# SERDES_16G0 register map
Vendor: Texas Instruments
Registers are 32-bit, read-write, reset 0x0 unless marked. A register's access mark holds for its fields unless they carry their own. Offsets are as the file gives them; [hi:lo] are bit positions; {n}, {i} and the like mark numbered series.

## SERDES_16G0 (part 3 of 5)
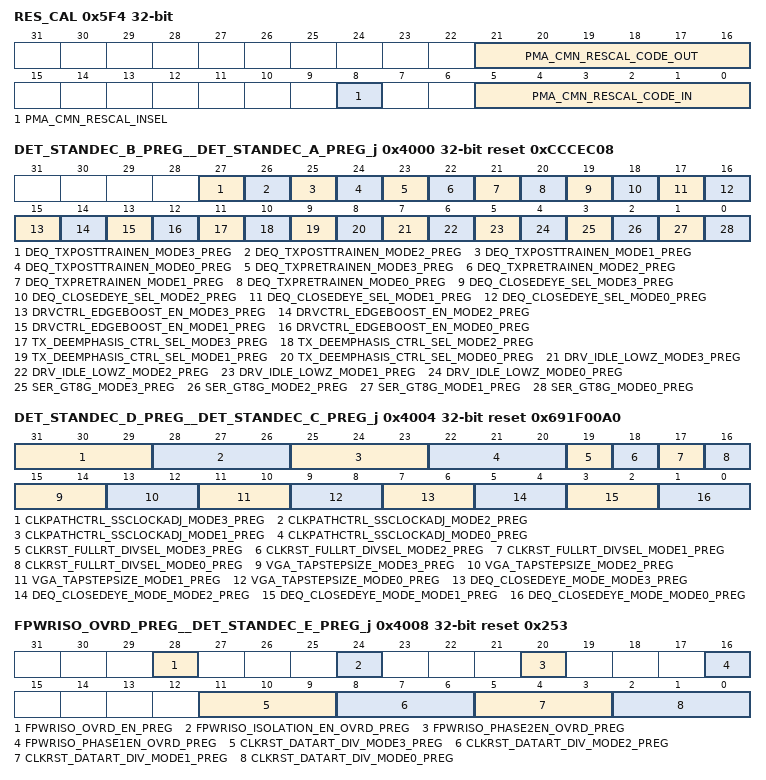
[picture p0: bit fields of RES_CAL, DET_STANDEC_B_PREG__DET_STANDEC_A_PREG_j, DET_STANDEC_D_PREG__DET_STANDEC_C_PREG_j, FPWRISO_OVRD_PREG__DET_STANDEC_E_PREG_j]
0x5F4 RES_CAL access per field — The Resistor Calibration register is used to allow the elimination of the external resistor on multiple macros.
  [21:16] PMA_CMN_RESCAL_CODE_OUT ro — This is the current value of the pma_cmn_rescal_code_out from the SERDES, and can be used to set pma_cmn_rescal_code_in for other macros.
  [8] PMA_CMN_RESCAL_INSEL rw — Common resistor calibration selection -
  [5:0] PMA_CMN_RESCAL_CODE_IN rw — External common resistor calibration result - Resistor calibration result from another Serdes PCIe PHY.
0x5FC DIAG_TEST — The Diagnostic Test Register allows the system to validate the read and write of all data bits.
  [31:0] DIAG_REG — Diagnostic register.
0x4000 DET_STANDEC_B_PREG__DET_STANDEC_A_PREG_j reset 0xCCCEC08 — Standard decoder register A. Offset = 4000h + (j * 400h); where j = 0h to 1h
  [27] DEQ_TXPOSTTRAINEN_MODE3_PREG — This value sets the deq_txposttrainen from the Lane Standards Decoder when xcvr_standard_mode_ln_{15:0}[2:0] is 3'b011.
  [26] DEQ_TXPOSTTRAINEN_MODE2_PREG — This value sets the deq_txposttrainen from the Lane Standards Decoder when xcvr_standard_mode_ln_{15:0}[2:0] is 3'b010.
  [25] DEQ_TXPOSTTRAINEN_MODE1_PREG — This value sets the deq_txposttrainen from the Lane Standards Decoder when xcvr_standard_mode_ln_{15:0}[2:0] is 3'b001.
  [24] DEQ_TXPOSTTRAINEN_MODE0_PREG — This value sets the deq_txposttrainen from the Lane Standards Decoder when xcvr_standard_mode_ln_{15:0}[2:0] is 3'b000.
  [23] DEQ_TXPRETRAINEN_MODE3_PREG — This value sets the deq_txpretrainen from the Lane Standards Decoder when xcvr_standard_mode_ln_{15:0}[2:0] is 3'b011.
  [22] DEQ_TXPRETRAINEN_MODE2_PREG — This value sets the deq_txpretrainen from the Lane Standards Decoder when xcvr_standard_mode_ln_{15:0}[2:0] is 3'b010.
  [21] DEQ_TXPRETRAINEN_MODE1_PREG — This value sets the deq_txpretrainen from the Lane Standards Decoder when xcvr_standard_mode_ln_{15:0}[2:0] is 3'b001.
  [20] DEQ_TXPRETRAINEN_MODE0_PREG — This value sets the deq_txpretrainen from the Lane Standards Decoder when xcvr_standard_mode_ln_{15:0}[2:0] is 3'b000.
  [19] DEQ_CLOSEDEYE_SEL_MODE3_PREG — This value sets the deq_closedeye_sel from the Lane Standards Decoder when xcvr_standard_mode_ln_{15:0}[2:0] is 3'b011.
  [18] DEQ_CLOSEDEYE_SEL_MODE2_PREG — This value sets the deq_closedeye_sel from the Lane Standards Decoder when xcvr_standard_mode_ln_{15:0}[2:0] is 3'b010.
  [17] DEQ_CLOSEDEYE_SEL_MODE1_PREG — This value sets the deq_closedeye_sel from the Lane Standards Decoder when xcvr_standard_mode_ln_{15:0}[2:0] is 3'b001.
  [16] DEQ_CLOSEDEYE_SEL_MODE0_PREG — This value sets the deq_closedeye_sel from the Lane Standards Decoder when xcvr_standard_mode_ln_{15:0}[2:0] is 3'b000.
  [15] DRVCTRL_EDGEBOOST_EN_MODE3_PREG — Active high enable for the transmit driver edgeboost function when xcvr_standard_mode_ln_{15:0}[2:0] is 3'b011.
  [14] DRVCTRL_EDGEBOOST_EN_MODE2_PREG — Active high enable for the transmit driver edgeboost function when xcvr_standard_mode_ln_{15:0}[2:0] is 3'b010.
  [13] DRVCTRL_EDGEBOOST_EN_MODE1_PREG — Active high enable for the transmit driver edgeboost function when xcvr_standard_mode_ln_{15:0}[2:0] is 3'b001.
  [12] DRVCTRL_EDGEBOOST_EN_MODE0_PREG — Active high enable for the transmit driver edgeboost function when xcvr_standard_mode_ln_{15:0}[2:0] is 3'b000.
  [11] TX_DEEMPHASIS_CTRL_SEL_MODE3_PREG — This value sets the tx_deemphasis_ctrl_sel from the Lane Standards Decoder when xcvr_standard_mode_ln_{15:0}[2:0] is 3'b011.
  [10] TX_DEEMPHASIS_CTRL_SEL_MODE2_PREG — This value sets the tx_deemphasis_ctrl_sel from the Lane Standards Decoder when xcvr_standard_mode_ln_{15:0}[2:0] is 3'b010.
  [9] TX_DEEMPHASIS_CTRL_SEL_MODE1_PREG — This value sets the tx_deemphasis_ctrl_sel from the Lane Standards Decoder when xcvr_standard_mode_ln_{15:0}[2:0] is 3'b001.
  [8] TX_DEEMPHASIS_CTRL_SEL_MODE0_PREG — This value sets the tx_deemphasis_ctrl_sel from the Lane Standards Decoder when xcvr_standard_mode_ln_{15:0}[2:0] is 3'b000.
  [7] DRV_IDLE_LOWZ_MODE3_PREG — Asserting this value lowers the impedance of the transmit driver common-mode impedance when xcvr_standard_mode_ln_{15:0}[2:0] is 3'b011.
  [6] DRV_IDLE_LOWZ_MODE2_PREG — Asserting this value lowers the impedance of the transmit driver common-mode impedance when xcvr_standard_mode_ln_{15:0}[2:0] is 3'b010.
  [5] DRV_IDLE_LOWZ_MODE1_PREG — Asserting this value lowers the impedance of the transmit driver common-mode impedance when xcvr_standard_mode_ln_{15:0}[2:0] is 3'b001.
  [4] DRV_IDLE_LOWZ_MODE0_PREG — Asserting this value lowers the impedance of the transmit driver common-mode impedance when xcvr_standard_mode_ln_{15:0}[2:0] is 3'b011.
  [3] SER_GT8G_MODE3_PREG — This value overrides the ser_gt8g from the Lane Standards Decoder when xcvr_standard_mode_ln_{15:0}[2:0] is 3'b011.
  [2] SER_GT8G_MODE2_PREG — This value overrides the ser_gt8g from the Lane Standards Decoder when xcvr_standard_mode_ln_{15:0}[2:0] is 3'b010.
  [1] SER_GT8G_MODE1_PREG — This value overrides the ser_gt8g from the Lane Standards Decoder when xcvr_standard_mode_ln_{15:0}[2:0] is 3'b001.
  [0] SER_GT8G_MODE0_PREG — This value overrides the ser_gt8g from the Lane Standards Decoder when xcvr_standard_mode_ln_{15:0}[2:0] is 3'b000.
0x4004 DET_STANDEC_D_PREG__DET_STANDEC_C_PREG_j reset 0x691F00A0 — Standard decoder register C. Offset = 4004h + (j * 400h); where j = 0h to 1h
  [31:29] CLKPATHCTRL_SSCLOCKADJ_MODE3_PREG — This value sets the clkpathctrl_ssclockadj from the Lane Standards Decoder when xcvr_standard_mode_ln_{15:0}[2:0] is 3'b011.
  [28:26] CLKPATHCTRL_SSCLOCKADJ_MODE2_PREG — This value sets the clkpathctrl_ssclockadj from the Lane Standards Decoder when xcvr_standard_mode_ln_{15:0}[2:0] is 3'b010.
  [25:23] CLKPATHCTRL_SSCLOCKADJ_MODE1_PREG — This value sets the clkpathctrl_ssclockadj from the Lane Standards Decoder when xcvr_standard_mode_ln_{15:0}[2:0] is 3'b001.
  [22:20] CLKPATHCTRL_SSCLOCKADJ_MODE0_PREG — This value sets the clkpathctrl_ssclockadj from the Lane Standards Decoder when xcvr_standard_mode_ln_{15:0}[2:0] is 3'b000.
  [19] CLKRST_FULLRT_DIVSEL_MODE3_PREG — This value sets the clkrst_fullrt_div2sel from the Lane Standards Decoder when xcvr_standard_mode_ln_{15:0}[2:0] is 3'b011.
  [18] CLKRST_FULLRT_DIVSEL_MODE2_PREG — This value sets the clkrst_fullrt_div2sel from the Lane Standards Decoder when xcvr_standard_mode_ln_{15:0}[2:0] is 3'b010.
  [17] CLKRST_FULLRT_DIVSEL_MODE1_PREG — This value sets the clkrst_fullrt_div2sel from the Lane Standards Decoder when xcvr_standard_mode_ln_{15:0}[2:0] is 3'b001.
  [16] CLKRST_FULLRT_DIVSEL_MODE0_PREG — This value sets the clkrst_fullrt_div2sel from the Lane Standards Decoder when xcvr_standard_mode_ln_{15:0}[2:0] is 3'b000.
  [15:14] VGA_TAPSTEPSIZE_MODE3_PREG — Receive data path offset correction current trim when xcvr_standard_mode_ln_{15:0}[2:0] is 3'b011:
  [13:12] VGA_TAPSTEPSIZE_MODE2_PREG — Receive data path offset correction current trim when xcvr_standard_mode_ln_{15:0}[2:0] is 3'b010:
  [11:10] VGA_TAPSTEPSIZE_MODE1_PREG — Receive data path offset correction current trim when xcvr_standard_mode_ln_{15:0}[2:0] is 3'b 001:
  [9:8] VGA_TAPSTEPSIZE_MODE0_PREG — Receive data path offset correction current trim when xcvr_standard_mode_ln_{15:0}[2:0] is 3'b000:
  [7:6] DEQ_CLOSEDEYE_MODE_MODE3_PREG — This value sets the deq_closedeye_mode from the Lane Standards Decoder when xcvr_standard_mode_ln_{15:0}[2:0] is 3'b011.
  [5:4] DEQ_CLOSEDEYE_MODE_MODE2_PREG — This value sets the deq_closedeye_mode from the Lane Standards Decoder when xcvr_standard_mode_ln_{15:0}[2:0] is 3'b010.
  [3:2] DEQ_CLOSEDEYE_MODE_MODE1_PREG — This value sets the deq_closedeye_mode from the Lane Standards Decoder when xcvr_standard_mode_ln_{15:0}[2:0] is 3'b001.
  [1:0] DEQ_CLOSEDEYE_MODE_MODE0_PREG — This value sets the deq_closedeye_mode from the Lane Standards Decoder when xcvr_standard_mode_ln_{15:0}[2:0] is 3'b000.
0x4008 FPWRISO_OVRD_PREG__DET_STANDEC_E_PREG_j reset 0x253 — Standard decoder register E. Offset = 4008h + (j * 400h); where j = 0h to 1h
  [28] FPWRISO_OVRD_EN_PREG — Lane power-gated supply island active high override enable:
  [24] FPWRISO_ISOLATION_EN_OVRD_PREG — Lane power-gated supply island isolation override:
  [20] FPWRISO_PHASE2EN_OVRD_PREG — Lane power-gated supply island phase2en override:
  [16] FPWRISO_PHASE1EN_OVRD_PREG — Lane power-gated supply island phase1en override:
  [11:9] CLKRST_DATART_DIV_MODE3_PREG — This value sets the clkrst_datart_divsel from the Lane Standards Decoder when xcvr_standard_mode_ln_{15:0}[2:0] is 3'b011.
  [8:6] CLKRST_DATART_DIV_MODE2_PREG — This value sets the clkrst_datart_divsel from the Lane Standards Decoder when xcvr_standard_mode_ln_{15:0}[2:0] is 3'b010.
  [5:3] CLKRST_DATART_DIV_MODE1_PREG — This value sets the clkrst_datart_divsel from the Lane Standards Decoder when xcvr_standard_mode_ln_{15:0}[2:0] is 3'b001.
  [2:0] CLKRST_DATART_DIV_MODE0_PREG — This value sets the clkrst_datart_divsel from the Lane Standards Decoder when xcvr_standard_mode_ln_{15:0}[2:0] is 3'b000.
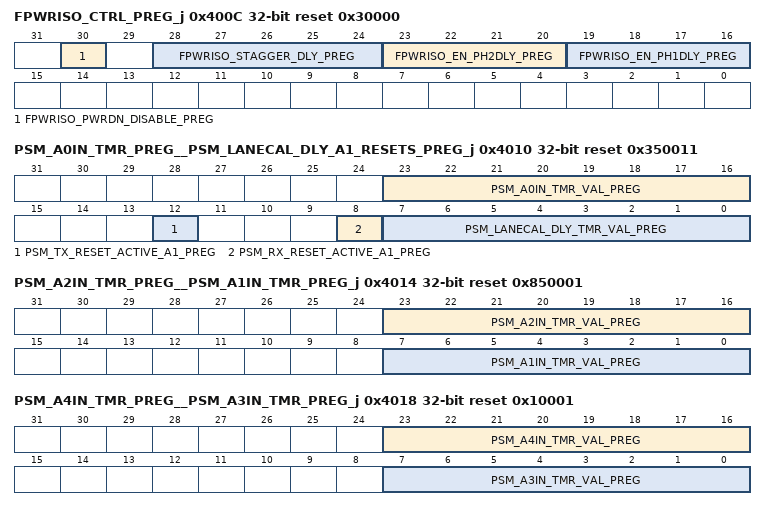
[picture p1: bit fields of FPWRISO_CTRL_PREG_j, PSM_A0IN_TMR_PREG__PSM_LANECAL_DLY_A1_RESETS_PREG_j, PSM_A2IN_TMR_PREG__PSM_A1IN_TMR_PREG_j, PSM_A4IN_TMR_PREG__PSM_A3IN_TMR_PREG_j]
0x400C FPWRISO_CTRL_PREG_j reset 0x30000 — Lane power-gated supply island control register. Offset = 400Ch + (j * 400h); where j = 0h to 1h
  [30] FPWRISO_PWRDN_DISABLE_PREG — Power down disable:
  [28:24] FPWRISO_STAGGER_DLY_PREG — Lane to Lane power island enable/disable stagger time:
  [23:20] FPWRISO_EN_PH2DLY_PREG — Power enable phase 2 timer value:
  [19:16] FPWRISO_EN_PH1DLY_PREG — Power enable phase 1 timer value:
0x4010 PSM_A0IN_TMR_PREG__PSM_LANECAL_DLY_A1_RESETS_PREG_j reset 0x350011 — Power State Machine lane calibration delay timer and A1 resets register. Link control register; only valid in master lane. Offset = 4010h + (j * 400h); where j = 0h to 1h
  [23:16] PSM_A0IN_TMR_VAL_PREG — A0 in delay state timer value :
  [12] PSM_TX_RESET_ACTIVE_A1_PREG — When asserted, the transmit path resets will be asserted in the A1 power state.
  [8] PSM_RX_RESET_ACTIVE_A1_PREG — When asserted, the receive path resets will be asserted in the A1 power state.
  [7:0] PSM_LANECAL_DLY_TMR_VAL_PREG — Lane calibration delay state timer value :
0x4014 PSM_A2IN_TMR_PREG__PSM_A1IN_TMR_PREG_j reset 0x850001 — Power State Machine A1 in delay timer register. Offset = 4014h + (j * 400h); where j = 0h to 1h
  [23:16] PSM_A2IN_TMR_VAL_PREG — A2 in delay state timer value :
  [7:0] PSM_A1IN_TMR_VAL_PREG — A1 in delay state timer value :
0x4018 PSM_A4IN_TMR_PREG__PSM_A3IN_TMR_PREG_j reset 0x10001 — Power State Machine A3 in delay timer register. Link control register; only valid in master lane. Offset = 4018h + (j * 400h); where j = 0h to 1h
  [23:16] PSM_A4IN_TMR_VAL_PREG — A4 in delay state timer value :
  [7:0] PSM_A3IN_TMR_VAL_PREG — A3 in delay state timer value :
0x401C PSM_A0OUT_TMR_PREG_j reset 0x10000 — Power State Machine A0 out delay timer register. Link control register; only valid in master lane. Offset = 401Ch + (j * 400h); where j = 0h to 1h
  [19:16] PSM_A0OUT_TMR_VAL_PREG — A0 out delay state timer value :
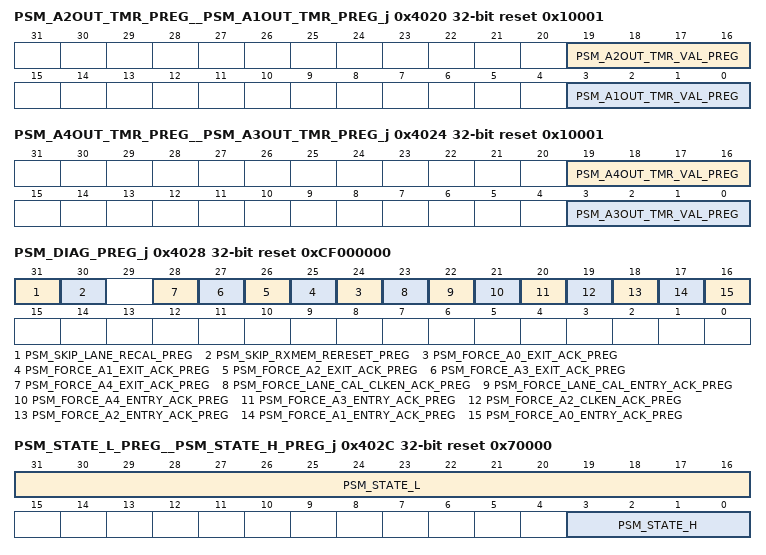
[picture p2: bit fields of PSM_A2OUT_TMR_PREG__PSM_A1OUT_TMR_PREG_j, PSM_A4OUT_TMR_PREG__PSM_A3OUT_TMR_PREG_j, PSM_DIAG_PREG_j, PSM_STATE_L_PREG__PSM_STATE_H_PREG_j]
0x4020 PSM_A2OUT_TMR_PREG__PSM_A1OUT_TMR_PREG_j reset 0x10001 — Power State Machine A1 out delay timer register. Link control register; only valid in master lane. Offset = 4020h + (j * 400h); where j = 0h to 1h
  [19:16] PSM_A2OUT_TMR_VAL_PREG — A2 out delay state timer value :
  [3:0] PSM_A1OUT_TMR_VAL_PREG — A1 out delay state timer value :
0x4024 PSM_A4OUT_TMR_PREG__PSM_A3OUT_TMR_PREG_j reset 0x10001 — Power State Machine A3 out delay timer register. Link control register; only valid in master lane. Offset = 4024h + (j * 400h); where j = 0h to 1h
  [19:16] PSM_A4OUT_TMR_VAL_PREG — A4 out delay state timer value :
  [3:0] PSM_A3OUT_TMR_VAL_PREG — A3 out delay state timer value :
0x4028 PSM_DIAG_PREG_j reset 0xCF000000 — Power State Machine diagnostic register. Link control register; only valid in master lane. Offset = 4028h + (j * 400h); where j = 0h to 1h
  [31] PSM_SKIP_LANE_RECAL_PREG — Skip lane re-calibration :
  [30] PSM_SKIP_RXMEM_RERESET_PREG — Skip reset of receive clock and data path equalization and offset memories:
  [n+24] PSM_FORCE_A{n}_EXIT_ACK_PREG (n=0..4) — Force A{n} exit acknowledge :
  [23] PSM_FORCE_LANE_CAL_CLKEN_ACK_PREG — Force lane calibration clken acknowledge :
  [22] PSM_FORCE_LANE_CAL_ENTRY_ACK_PREG — Force lane calibration entry acknowledge :
  [21] PSM_FORCE_A4_ENTRY_ACK_PREG — Force A4 entry acknowledge :
  [20] PSM_FORCE_A3_ENTRY_ACK_PREG — Force A3 entry acknowledge :
  [19] PSM_FORCE_A2_CLKEN_ACK_PREG — Force A2 clken acknowledge :
  [18] PSM_FORCE_A2_ENTRY_ACK_PREG — Force A2 entry acknowledge :
  [17] PSM_FORCE_A1_ENTRY_ACK_PREG — Force A1 entry acknowledge :
  [16] PSM_FORCE_A0_ENTRY_ACK_PREG — Force A0 entry acknowledge :
0x402C PSM_STATE_L_PREG__PSM_STATE_H_PREG_j ro reset 0x70000 — Power State Machine current state register high byte. Offset = 402Ch + (j * 400h); where j = 0h to 1h
  [31:16] PSM_STATE_L — Power state machine current state:
  [3:0] PSM_STATE_H — Power state machine current state:
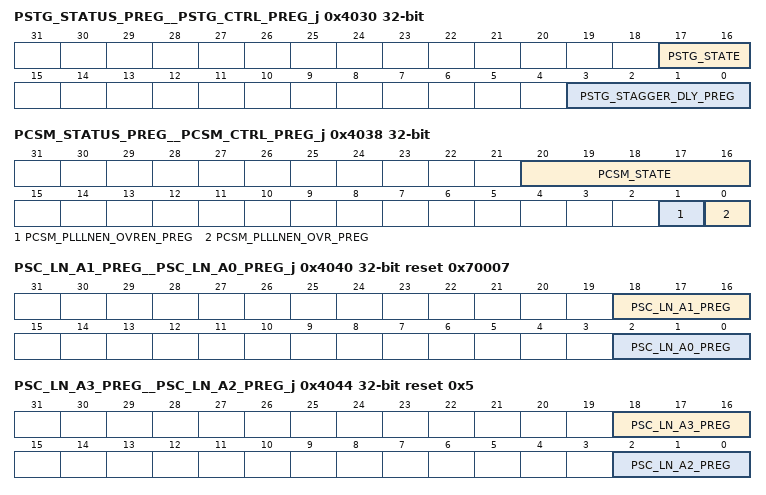
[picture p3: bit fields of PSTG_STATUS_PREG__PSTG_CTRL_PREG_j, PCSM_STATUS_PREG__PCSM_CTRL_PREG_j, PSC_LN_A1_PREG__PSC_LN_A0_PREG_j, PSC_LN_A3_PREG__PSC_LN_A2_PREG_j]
0x4030 PSTG_STATUS_PREG__PSTG_CTRL_PREG_j access per field — Power State Token Generator Control Register Offset = 4030h + (j * 400h); where j = 0h to 1h
  [17:16] PSTG_STATE ro — Power State Token Generator FSM state vector.
  [3:0] PSTG_STAGGER_DLY_PREG rw — Lane to Lane power state enable/disable stagger time:
0x4038 PCSM_STATUS_PREG__PCSM_CTRL_PREG_j access per field — PLL clock state machine control register Offset = 4038h + (j * 400h); where j = 0h to 1h
  [20:16] PCSM_STATE ro — PLL clock state machine control state vector.
  [1] PCSM_PLLLNEN_OVREN_PREG rw — PLLLN active high enable override enable:
  [0] PCSM_PLLLNEN_OVR_PREG rw — PLLLN active high enable override value:
0x4040 PSC_LN_A1_PREG__PSC_LN_A0_PREG_j reset 0x70007 — Lane A0 power state definition register. Offset = 4040h + (j * 400h); where j = 0h to 1h
  [18:16] PSC_LN_A1_PREG — Bit Description
  [2:0] PSC_LN_A0_PREG — Bit Description
0x4044 PSC_LN_A3_PREG__PSC_LN_A2_PREG_j reset 0x5 — Lane A2 power state definition register. Offset = 4044h + (j * 400h); where j = 0h to 1h
  [18:16] PSC_LN_A3_PREG — Bit Description
  [2:0] PSC_LN_A2_PREG — Bit Description
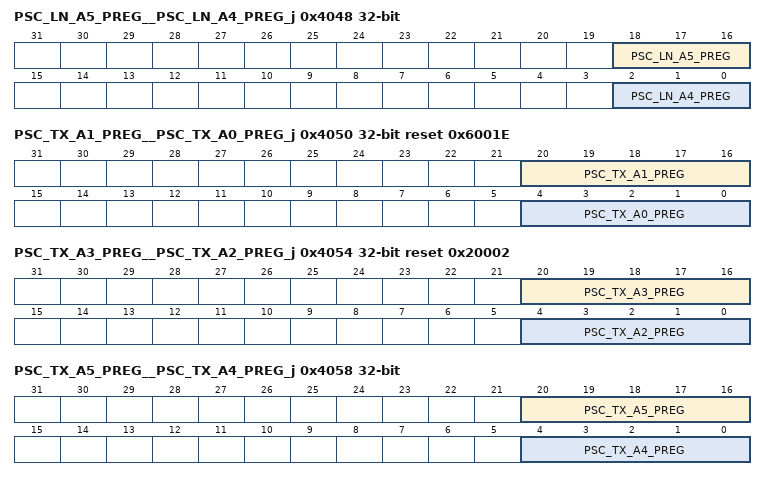
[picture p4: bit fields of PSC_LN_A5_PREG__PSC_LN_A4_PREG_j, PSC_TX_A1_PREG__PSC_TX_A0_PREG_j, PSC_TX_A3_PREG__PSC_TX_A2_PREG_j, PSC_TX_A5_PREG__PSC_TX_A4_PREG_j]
0x4048 PSC_LN_A5_PREG__PSC_LN_A4_PREG_j — Lane A4 power state definition register. Offset = 4048h + (j * 400h); where j = 0h to 1h
  [18:16] PSC_LN_A5_PREG — Bit Description
  [2:0] PSC_LN_A4_PREG — Bit Description
0x404C PSC_LN_IDLE_PREG_j — Lane idle power state definition register. Offset = 404Ch + (j * 400h); where j = 0h to 1h
  [2:0] PSC_LN_IDLE_PREG — Bit Description
0x4050 PSC_TX_A1_PREG__PSC_TX_A0_PREG_j reset 0x6001E — Transmit A0 power state definition register. Offset = 4050h + (j * 400h); where j = 0h to 1h
  [20:16] PSC_TX_A1_PREG — Bit Description
  [4:0] PSC_TX_A0_PREG — Bit Description
0x4054 PSC_TX_A3_PREG__PSC_TX_A2_PREG_j reset 0x20002 — Transmit A2 power state definition register. Offset = 4054h + (j * 400h); where j = 0h to 1h
  [20:16] PSC_TX_A3_PREG — Bit Description
  [4:0] PSC_TX_A2_PREG — Bit Description
0x4058 PSC_TX_A5_PREG__PSC_TX_A4_PREG_j — Transmit A4 power state definition register. Offset = 4058h + (j * 400h); where j = 0h to 1h
  [20:16] PSC_TX_A5_PREG — Bit Description
  [4:0] PSC_TX_A4_PREG — Bit Description
0x405C PSC_TX_IDLE_PREG_j — Transmit idle power state definition register. Offset = 405Ch + (j * 400h); where j = 0h to 1h
  [4:0] PSC_TX_IDLE_PREG — Bit Description
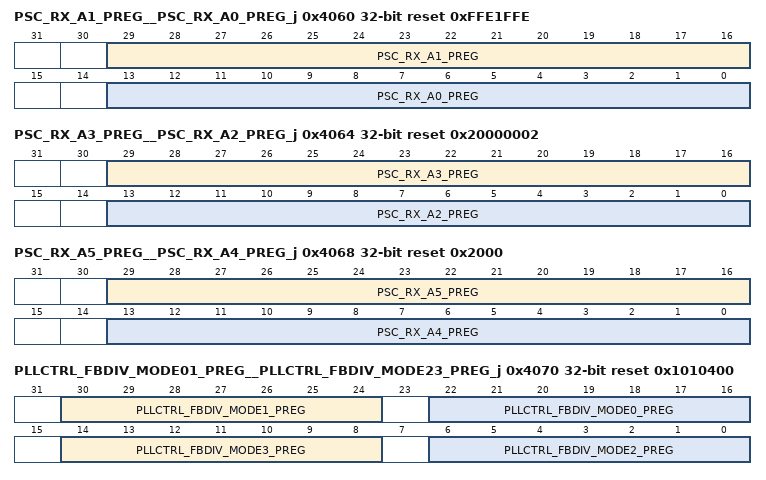
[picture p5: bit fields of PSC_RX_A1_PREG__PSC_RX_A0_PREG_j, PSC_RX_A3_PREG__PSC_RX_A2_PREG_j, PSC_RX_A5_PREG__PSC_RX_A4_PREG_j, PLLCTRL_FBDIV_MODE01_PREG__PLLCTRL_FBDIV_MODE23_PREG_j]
0x4060 PSC_RX_A1_PREG__PSC_RX_A0_PREG_j reset 0xFFE1FFE — Receive A0 power state definition register. Offset = 4060h + (j * 400h); where j = 0h to 1h
  [29:16] PSC_RX_A1_PREG — Bit Description
  [13:0] PSC_RX_A0_PREG — Bit Description
0x4064 PSC_RX_A3_PREG__PSC_RX_A2_PREG_j reset 0x20000002 — Receive A2 power state definition register. Offset = 4064h + (j * 400h); where j = 0h to 1h
  [29:16] PSC_RX_A3_PREG — Bit Description
  [13:0] PSC_RX_A2_PREG — Bit Description
0x4068 PSC_RX_A5_PREG__PSC_RX_A4_PREG_j reset 0x2000 — Receive A4 power state definition register. Offset = 4068h + (j * 400h); where j = 0h to 1h
  [29:16] PSC_RX_A5_PREG — Bit Description
  [13:0] PSC_RX_A4_PREG — Bit Description
0x406C PSC_RX_IDLE_PREG_j — Receive Idle power state definition register. Offset = 406Ch + (j * 400h); where j = 0h to 1h
  [13:0] PSC_RX_IDLE_PREG — Bit Description
0x4070 PLLCTRL_FBDIV_MODE01_PREG__PLLCTRL_FBDIV_MODE23_PREG_j reset 0x1010400 — PLLLN feedback divider control in standard modes 2 and 3. Offset = 4070h + (j * 400h); where j = 0h to 1h
  [30:24] PLLCTRL_FBDIV_MODE1_PREG — This value sets the feedback divider ratio from the Lane Standards Decoder when xcvr_standard_mode_ln_{15:0}[2:0] is 3'b001.
  [22:16] PLLCTRL_FBDIV_MODE0_PREG — This value sets the feedback divider ratio from the Lane Standards Decoder when xcvr_standard_mode_ln_{15:0}[2:0] is 3'b000.
  [14:8] PLLCTRL_FBDIV_MODE3_PREG — This value sets the feedback divider ratio from the Lane Standards Decoder when xcvr_standard_mode_ln_{15:0}[2:0] is 3'b011.
  [6:0] PLLCTRL_FBDIV_MODE2_PREG — This value sets the feedback divider ratio from the Lane Standards Decoder when xcvr_standard_mode_ln_{15:0}[2:0] is 3'b010.
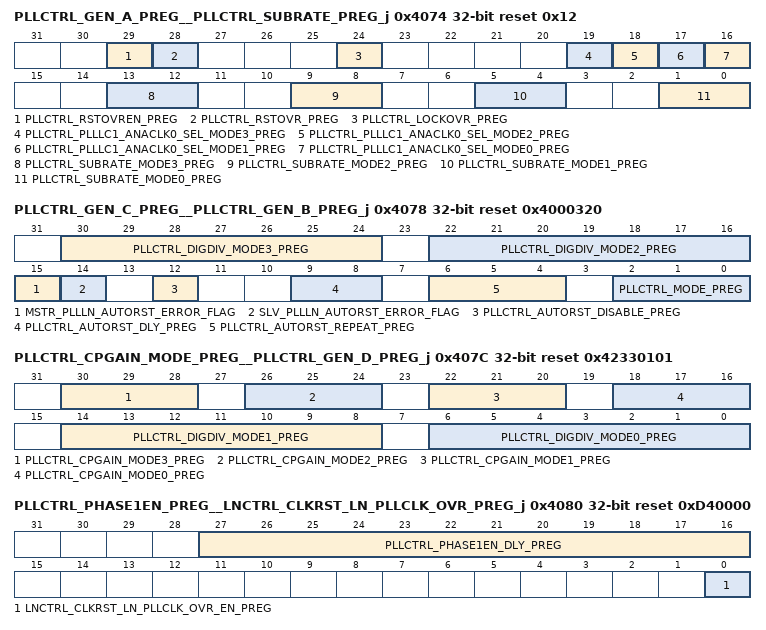
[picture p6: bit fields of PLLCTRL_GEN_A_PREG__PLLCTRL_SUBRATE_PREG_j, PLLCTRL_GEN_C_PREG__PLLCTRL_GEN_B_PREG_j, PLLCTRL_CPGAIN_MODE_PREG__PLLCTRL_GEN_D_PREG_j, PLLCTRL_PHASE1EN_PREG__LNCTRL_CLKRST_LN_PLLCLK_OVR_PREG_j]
0x4074 PLLCTRL_GEN_A_PREG__PLLCTRL_SUBRATE_PREG_j reset 0x12 — PLLLN subrate control register. Offset = 4074h + (j * 400h); where j = 0h to 1h
  [29] PLLCTRL_RSTOVREN_PREG — PLLLN reset active high override enable.
  [28] PLLCTRL_RSTOVR_PREG — When pllctrl_rstovren_preg is asserted high, this active high bit overrides the reset.
  [24] PLLCTRL_LOCKOVR_PREG — Forces the lock indication from the PLLln high as enters into main digital.
  [19] PLLCTRL_PLLLC1_ANACLK0_SEL_MODE3_PREG — PLLLN reference selection when xcvr_standard_mode_ln_{15:0}[2:0] is 3'b011.
  [18] PLLCTRL_PLLLC1_ANACLK0_SEL_MODE2_PREG — PLLLN reference selection when xcvr_standard_mode_ln_{15:0}[2:0] is 3'b010.
  [17] PLLCTRL_PLLLC1_ANACLK0_SEL_MODE1_PREG — PLLLN reference selection when xcvr_standard_mode_ln_{15:0}[2:0] is 3'b001.
  [16] PLLCTRL_PLLLC1_ANACLK0_SEL_MODE0_PREG — PLLLN reference selection when xcvr_standard_mode_ln_{15:0}[2:0] is 3'b000.
  [13:12] PLLCTRL_SUBRATE_MODE3_PREG — This value sets the subrate divider ratio from the Lane Standards Decoder when xcvr_standard_mode_ln_{15:0}[2:0] is 3'b011.
  [9:8] PLLCTRL_SUBRATE_MODE2_PREG — This value sets the subrate divider ratio from the Lane Standards Decoder when xcvr_standard_mode_ln_{15:0}[2:0] is 3'b010.
  [5:4] PLLCTRL_SUBRATE_MODE1_PREG — This value sets the subrate divider ratio from the Lane Standards Decoder when xcvr_standard_mode_ln_{15:0}[2:0] is 3'b001.
  [1:0] PLLCTRL_SUBRATE_MODE0_PREG — This value sets the subrate divider ratio from the Lane Standards Decoder when xcvr_standard_mode_ln_{15:0}[2:0] is 3'b000.
0x4078 PLLCTRL_GEN_C_PREG__PLLCTRL_GEN_B_PREG_j access per field reset 0x4000320 — PLLLN general control register B. Offset = 4078h + (j * 400h); where j = 0h to 1h
  [30:24] PLLCTRL_DIGDIV_MODE3_PREG rw — PLLLN digclk divider selection when xcvr_standard_mode_ln_{15:0}[2:0] is 3'b011.
  [22:16] PLLCTRL_DIGDIV_MODE2_PREG rw — PLLLN digclk divider selection when xcvr_standard_mode_ln_{15:0}[2:0] is 3'b010.
  [15] MSTR_PLLLN_AUTORST_ERROR_FLAG ro — Master lane PLLLN active high auto reset error flag.
  [14] SLV_PLLLN_AUTORST_ERROR_FLAG ro — Combined slave lanes PLLLN active high auto reset error flag.
  [12] PLLCTRL_AUTORST_DISABLE_PREG rw — PLLLN active high auto reset disable.
  [9:8] PLLCTRL_AUTORST_DLY_PREG rw — PLLLN auto reset delay selection:
  [6:4] PLLCTRL_AUTORST_REPEAT_PREG rw — PLLLN auto reset maximum attempt selection.
  [2:0] PLLCTRL_MODE_PREG rw — PLLLN operating mode as defined below:
0x407C PLLCTRL_CPGAIN_MODE_PREG__PLLCTRL_GEN_D_PREG_j reset 0x42330101 — PLLLN general control register D. Offset = 407Ch + (j * 400h); where j = 0h to 1h
  [30:28] PLLCTRL_CPGAIN_MODE3_PREG — PLLLN charge pump gain when xcvr_standard_mode_ln_PLLCTRL_AUTORST_DLY_PREG is 3'b011.
  [26:24] PLLCTRL_CPGAIN_MODE2_PREG — PLLLN charge pump gain when xcvr_standard_mode_ln_PLLCTRL_AUTORST_DLY_PREG is 3'b010.
  [22:20] PLLCTRL_CPGAIN_MODE1_PREG — PLLLN charge pump gain when xcvr_standard_mode_ln_PLLCTRL_AUTORST_DLY_PREG is 3'b001.
  [18:16] PLLCTRL_CPGAIN_MODE0_PREG — PLLLN charge pump gain when xcvr_standard_mode_ln_PLLCTRL_AUTORST_DLY_PREG is 3'b000.
  [14:8] PLLCTRL_DIGDIV_MODE1_PREG — PLLLN digclk divider selection when xcvr_standard_mode_ln_PLLCTRL_AUTORST_DLY_PREG is 3'b001.
  [6:0] PLLCTRL_DIGDIV_MODE0_PREG — PLLLN digclk divider selection when xcvr_standard_mode_ln_PLLCTRL_AUTORST_DLY_PREG is 3'b000.
0x4080 PLLCTRL_PHASE1EN_PREG__LNCTRL_CLKRST_LN_PLLCLK_OVR_PREG_j reset 0xD40000 — Diagnostic access to cmn_sdosc_clk Offset = 4080h + (j * 400h); where j = 0h to 1h
  [27:16] PLLCTRL_PHASE1EN_DLY_PREG — PLLLN phase1en delay time in xcvr_psmclk_ln_{15:0} periods:
  [0] LNCTRL_CLKRST_LN_PLLCLK_OVR_EN_PREG — When asserted the cmn_sdosc_clk is used to source the ln_pllclk_fullrt.
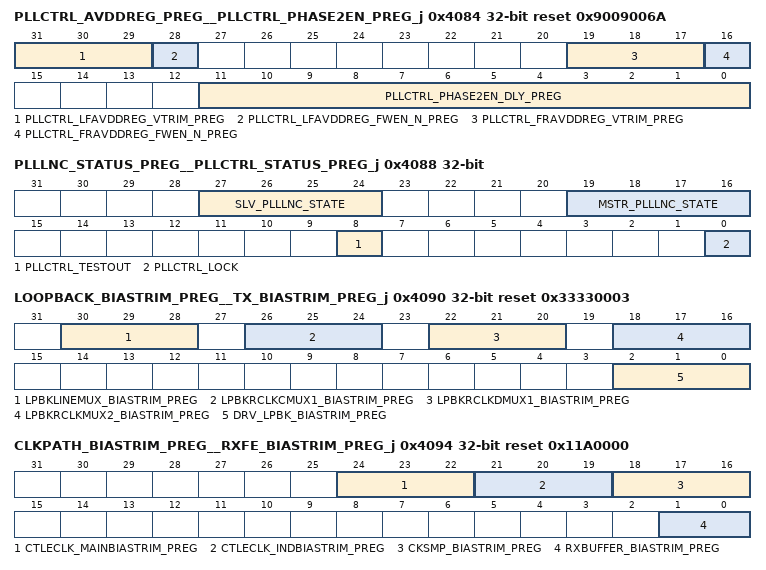
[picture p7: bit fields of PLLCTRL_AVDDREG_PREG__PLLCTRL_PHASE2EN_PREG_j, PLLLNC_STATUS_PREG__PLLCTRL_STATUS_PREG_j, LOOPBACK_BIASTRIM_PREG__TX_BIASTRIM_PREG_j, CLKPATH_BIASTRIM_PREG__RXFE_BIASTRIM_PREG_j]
0x4084 PLLCTRL_AVDDREG_PREG__PLLCTRL_PHASE2EN_PREG_j reset 0x9009006A — PLLLN phase2 enable delay control register. Offset = 4084h + (j * 400h); where j = 0h to 1h
  [31:29] PLLCTRL_LFAVDDREG_VTRIM_PREG — PLLLN low frequency block regulator voltage trim.
  [28] PLLCTRL_LFAVDDREG_FWEN_N_PREG — PLLLN active low firewall enable forcing for signal driven from lfavddreg power island.
  [19:17] PLLCTRL_FRAVDDREG_VTRIM_PREG — PLLLN full rate block regulator voltage trim.
  [16] PLLCTRL_FRAVDDREG_FWEN_N_PREG — PLLLN active low firewall enable forcing for signal driven from fravddreg power island.
  [11:0] PLLCTRL_PHASE2EN_DLY_PREG — PLLLN phase2en delay time in xcvr_psmclk_ln_{15:0} periods:
0x4088 PLLLNC_STATUS_PREG__PLLCTRL_STATUS_PREG_j ro — PLLLN status register. Offset = 4088h + (j * 400h); where j = 0h to 1h
  [27:24] SLV_PLLLNC_STATE — Slave lane PLL control state machine state vector.
  [19:16] MSTR_PLLLNC_STATE — Master lane PLL control state machine state vector.
  [8] PLLCTRL_TESTOUT — PLLLN digital debug output.
  [0] PLLCTRL_LOCK — PLLLN active high lock flag.
0x4090 LOOPBACK_BIASTRIM_PREG__TX_BIASTRIM_PREG_j reset 0x33330003 — Transmit loopback bias current trim register. Offset = 4090h + (j * 400h); where j = 0h to 1h
  [30:28] LPBKLINEMUX_BIASTRIM_PREG — Receive line loopback multiplexor bias current binary encoded trim:
  [26:24] LPBKRCLKCMUX1_BIASTRIM_PREG — Receive recovered clock loopback clock path stage 1 multiplexer bias current binary encoded trim:
  [22:20] LPBKRCLKDMUX1_BIASTRIM_PREG — Receive recovered clock loopback data path stage 1 multiplexer bias current binary encoded trim:
  [18:16] LPBKRCLKMUX2_BIASTRIM_PREG — Receive recovered clock loopback stage 2 multiplexer bias current binary encoded trim:
  [2:0] DRV_LPBK_BIASTRIM_PREG — Transmit bias current binary encoded trim shared for both serial and line/recovered clock loopbacks:
0x4094 CLKPATH_BIASTRIM_PREG__RXFE_BIASTRIM_PREG_j reset 0x11A0000 — Receive front-end bias current trim register Offset = 4094h + (j * 400h); where j = 0h to 1h
  [24:22] CTLECLK_MAINBIASTRIM_PREG — Receive clock path clock CTLE main path bias current binary encoded trim:
  [21:19] CTLECLK_INDBIASTRIM_PREG — Receive clock path clock CTLE inductor circuitry bias current binary encoded trim:
  [18:16] CKSMP_BIASTRIM_PREG — Receive clock path clock sampler bias current binary encoded trim:
  [1:0] RXBUFFER_BIASTRIM_PREG — Receive buffer bias current binary encoded trim.
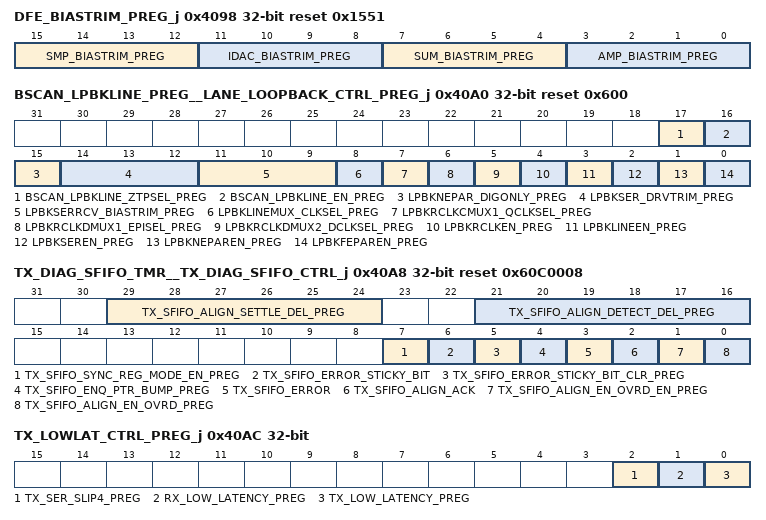
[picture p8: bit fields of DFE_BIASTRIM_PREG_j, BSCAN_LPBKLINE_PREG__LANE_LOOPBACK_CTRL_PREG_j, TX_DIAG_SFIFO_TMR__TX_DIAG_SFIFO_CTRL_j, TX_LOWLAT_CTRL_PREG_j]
0x4098 DFE_BIASTRIM_PREG_j reset 0x1551 — Receive data path DFE bias current trim register. Offset = 4098h + (j * 400h); where j = 0h to 1h
  [15:12] SMP_BIASTRIM_PREG — Receive data path DFE sampler bias current binary encoded trim:
  [11:8] IDAC_BIASTRIM_PREG — Receive data path DFE current DAC bias current binary encoded trim:
  [7:4] SUM_BIASTRIM_PREG — Receive data path DFE summer bias current binary encoded trim:
  [3:0] AMP_BIASTRIM_PREG — Receive data path DFE amplifier bias current binary encoded trim:
0x40A0 BSCAN_LPBKLINE_PREG__LANE_LOOPBACK_CTRL_PREG_j reset 0x600 — Local Lane loopback control register. Offset = 40A0h + (j * 400h); where j = 0h to 1h
  [17] BSCAN_LPBKLINE_ZTPSEL_PREG — Multiplexor selection for which boundary scan receiver is looped back:
  [16] BSCAN_LPBKLINE_EN_PREG — Active high enable for boundary scan receiver to driver line loopback.
  [15] LPBKNEPAR_DIGONLY_PREG — Active high digital only version of Near-end parallel loopback requiring no analog support other than reference clock reception.
  [14:12] LPBKSER_DRVTRIM_PREG — Trim setting for txana_lpbkser in serial loopback path:
  [11:9] LPBKSERRCV_BIASTRIM_PREG — Bias trim setting for rxana_lpbkserrcv in serial loopback path:
  [8] LPBKLINEMUX_CLKSEL_PREG — Line loopback source selection:
  [7] LPBKRCLKCMUX1_QCLKSEL_PREG — Recovered clock loopback clock path mux stage 1 selection:
  [6] LPBKRCLKDMUX1_EPISEL_PREG — Recovered clock loopback data path mux stage 1 selection:
  [5] LPBKRCLKDMUX2_DCLKSEL_PREG — Recovered clock loopback mux stage 2 selection:
  [4] LPBKRCLKEN_PREG — Recovered clock loopback active high enable:
  [3] LPBKLINEEN_PREG — Line side loopback active high enable:
  [2] LPBKSEREN_PREG — Serial loopback active high enable:
  [1] LPBKNEPAREN_PREG — Near end parallel loopback active high enable:
  [0] LPBKFEPAREN_PREG — Far end parallel loopback active high enable:
0x40A8 TX_DIAG_SFIFO_TMR__TX_DIAG_SFIFO_CTRL_j access per field reset 0x60C0008 — TX sync FIFO diagnostic control register Offset = 40A8h + (j * 400h); where j = 0h to 1h
  [29:24] TX_SFIFO_ALIGN_SETTLE_DEL_PREG rw — FIFO alignment settle delay:
  [21:16] TX_SFIFO_ALIGN_DETECT_DEL_PREG rw — FIFO alignment detect delay:
  [7] TX_SFIFO_SYNC_REG_MODE_EN_PREG rw — 1'b 0 : Normal FIFO operation.
  [6] TX_SFIFO_ERROR_STICKY_BIT ro — Sticky FIFO alignment error:
  [5] TX_SFIFO_ERROR_STICKY_BIT_CLR_PREG wo — Sticky FIFO alignment error clear:
  [4] TX_SFIFO_ENQ_PTR_BUMP_PREG rw — FIFO enqueue pointer bump:
  [3] TX_SFIFO_ERROR ro — FIFO alignment error:
  [2] TX_SFIFO_ALIGN_ACK ro — FIFO alignment acknowledge:
  [1] TX_SFIFO_ALIGN_EN_OVRD_EN_PREG rw — FIFO alignment enable override enable:
  [0] TX_SFIFO_ALIGN_EN_OVRD_PREG rw — FIFO alignment enable override:
0x40AC TX_LOWLAT_CTRL_PREG_j access per field — Ultra low latency mode control register Offset = 40ACh + (j * 400h); where j = 0h to 1h
  [2] TX_SER_SLIP4_PREG wo — Serializer slip by 4UI request:
  [1] RX_LOW_LATENCY_PREG rw — Receive ultra-low latency mode enable:
  [0] TX_LOW_LATENCY_PREG rw — Transmit ultra-low latency mode enable:
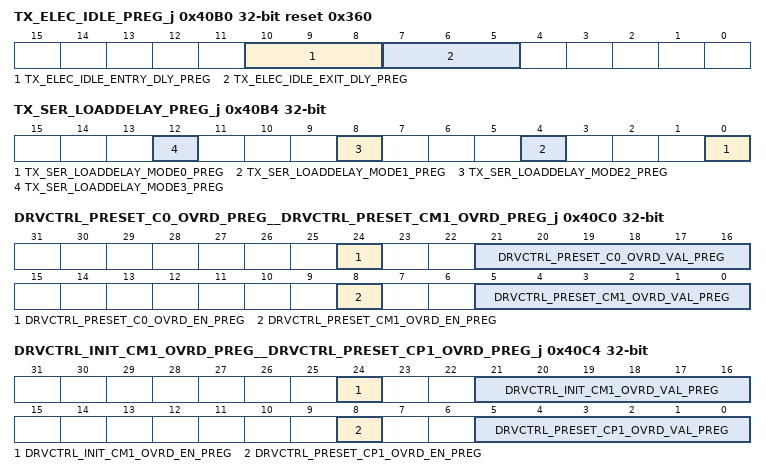
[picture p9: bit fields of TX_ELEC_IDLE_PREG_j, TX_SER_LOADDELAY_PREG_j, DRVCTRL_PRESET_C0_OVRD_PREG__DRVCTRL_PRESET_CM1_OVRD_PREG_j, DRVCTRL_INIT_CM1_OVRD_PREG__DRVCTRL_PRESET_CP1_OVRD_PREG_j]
0x40B0 TX_ELEC_IDLE_PREG_j reset 0x360 — Transmit electrical idle control register. Offset = 40B0h + (j * 400h); where j = 0h to 1h
  [10:8] TX_ELEC_IDLE_ENTRY_DLY_PREG — Transmit path electrical idle entry programmable delay:
  [7:5] TX_ELEC_IDLE_EXIT_DLY_PREG — Transmit path electrical idle exit programmable delay:
0x40B4 TX_SER_LOADDELAY_PREG_j — Tx serializer load delay control register. Offset = 40B4h + (j * 400h); where j = 0h to 1h
  [4n] TX_SER_LOADDELAY_MODE{n}_PREG (n=0..3) — Analog Serializer parallel data load delay.
0x40B8 TX_HSRRSM_STATUS_PREG_j ro — Transmit high speed reset release state machine status register. Offset = 40B8h + (j * 400h); where j = 0h to 1h
  [4:0] TX_HSRRSM_STATE — Transmit high speed reset release state machine state vector
0x40C0 DRVCTRL_PRESET_C0_OVRD_PREG__DRVCTRL_PRESET_CM1_OVRD_PREG_j — Transmit driver local preset pre-emphasis cursor override register. Offset = 40C0h + (j * 400h); where j = 0h to 1h
  [24] DRVCTRL_PRESET_C0_OVRD_EN_PREG — Local preset main cursor active high override enable.
  [21:16] DRVCTRL_PRESET_C0_OVRD_VAL_PREG — When drvctrl_preset_c0_ovrd_en_preg is asserted high, this value overrides the internally generated value for tx_local_tx_preset_coef_ln_{15:0} [11:6] following a tx_get_local_preset_coef_ln_{15:0} request.
  [8] DRVCTRL_PRESET_CM1_OVRD_EN_PREG — Local preset pre-emphasis cursor active high override enable.
  [5:0] DRVCTRL_PRESET_CM1_OVRD_VAL_PREG — When drvctrl_preset_cm1_ovrd_en_preg is asserted high, this value overrides the internally generated value for tx_local_tx_preset_coef_ln_{15:0} [5:0] following a tx_get_local_preset_coef_ln_{15:0} request.
0x40C4 DRVCTRL_INIT_CM1_OVRD_PREG__DRVCTRL_PRESET_CP1_OVRD_PREG_j — Transmit driver local preset post-emphasis cursor override register. Offset = 40C4h + (j * 400h); where j = 0h to 1h
  [24] DRVCTRL_INIT_CM1_OVRD_EN_PREG — Local init pre-emphasis cursor active high override enable.
  [21:16] DRVCTRL_INIT_CM1_OVRD_VAL_PREG — When drvctrl_init_cm1_ovrd_en_preg is asserted high, this value overrides the internally generated value for tx_local_tx_preset_coef_ln_{15:0} [5:0] following a tx_get_local_init_coef_ln_{15:0} request.
  [8] DRVCTRL_PRESET_CP1_OVRD_EN_PREG — Local preset post-emphasis cursor active high override enable.
  [5:0] DRVCTRL_PRESET_CP1_OVRD_VAL_PREG — When drvctrl_preset_cp1_ovrd_en_preg is asserted high, this value overrides the internally generated value for tx_local_tx_preset_coef_ln_{15:0} [17:12] following a tx_get_local_preset_coef_ln_{15:0} request.
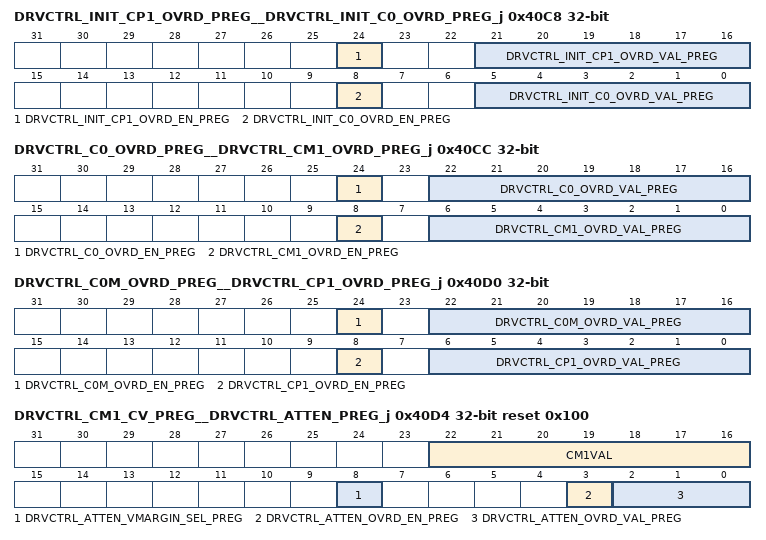
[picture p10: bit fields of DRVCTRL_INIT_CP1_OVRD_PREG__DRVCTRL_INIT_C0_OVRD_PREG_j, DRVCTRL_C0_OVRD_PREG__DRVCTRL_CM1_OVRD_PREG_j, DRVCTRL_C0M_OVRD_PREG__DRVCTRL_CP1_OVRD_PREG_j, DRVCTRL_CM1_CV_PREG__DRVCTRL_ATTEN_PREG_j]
0x40C8 DRVCTRL_INIT_CP1_OVRD_PREG__DRVCTRL_INIT_C0_OVRD_PREG_j — Transmit driver local init main cursor override register. Offset = 40C8h + (j * 400h); where j = 0h to 1h
  [24] DRVCTRL_INIT_CP1_OVRD_EN_PREG — Local init post-emphasis cursor active high override enable.
  [21:16] DRVCTRL_INIT_CP1_OVRD_VAL_PREG — When drvctrl_init_cp1_ovrd_en_preg is asserted high, this value overrides the internally generated value for tx_local_tx_preset_coef_ln_{15:0} [17:12] following a tx_get_local_init_coef_ln_{15:0} request.
  [8] DRVCTRL_INIT_C0_OVRD_EN_PREG — Local init main cursor active high override enable.
  [5:0] DRVCTRL_INIT_C0_OVRD_VAL_PREG — When drvctrl_init_c0_ovrd_en_preg is asserted high, this value overrides the internally generated value for tx_local_tx_preset_coef_ln_{15:0} [11:6] following a tx_get_local_init_coef_ln_{15:0} request.
0x40CC DRVCTRL_C0_OVRD_PREG__DRVCTRL_CM1_OVRD_PREG_j — Transmit driver pre-emphasis cursor override register. Offset = 40CCh + (j * 400h); where j = 0h to 1h
  [24] DRVCTRL_C0_OVRD_EN_PREG — Main cursor active high override enable.
  [22:16] DRVCTRL_C0_OVRD_VAL_PREG — When drvctrl_c0_ovrd_en_preg is asserted high, this value overrides the internally calculated main coefficient sent to the analog transmitter circuit.
  [8] DRVCTRL_CM1_OVRD_EN_PREG — Pre-emphasis cursor active high override enable.
  [6:0] DRVCTRL_CM1_OVRD_VAL_PREG — When drvctrl_cm1_ovrd_en_preg is asserted high, this value overrides the internally calculated pre-cursor coefficient sent to the analog transmitter circuit.
0x40D0 DRVCTRL_C0M_OVRD_PREG__DRVCTRL_CP1_OVRD_PREG_j — Transmit driver post-emphasis cursor override register. Offset = 40D0h + (j * 400h); where j = 0h to 1h
  [24] DRVCTRL_C0M_OVRD_EN_PREG — Margin cursor active high override enable.
  [22:16] DRVCTRL_C0M_OVRD_VAL_PREG — When drvctrl_c0m_ovrd_en_preg is asserted high, this value overrides the internally calculated margin coefficient sent to the analog transmitter circuit.
  [8] DRVCTRL_CP1_OVRD_EN_PREG — Post-emphasis cursor active high override enable.
  [6:0] DRVCTRL_CP1_OVRD_VAL_PREG — When drvctrl_cp1_ovrd_en_preg is asserted high, this value overrides the internally calculated post-emphasis coefficient sent to the analog transmitter circuit.
0x40D4 DRVCTRL_CM1_CV_PREG__DRVCTRL_ATTEN_PREG_j access per field reset 0x100 — Transmit driver attenuation control register. Offset = 40D4h + (j * 400h); where j = 0h to 1h
  [22:16] CM1VAL ro — Current pre-emphasis cursor value to analog driver.
  [8] DRVCTRL_ATTEN_VMARGIN_SEL_PREG rw — When asserted high, the driver attenuation is controlled through tx_vmargin_ln_{15:0}.
  [3] DRVCTRL_ATTEN_OVRD_EN_PREG rw — Driver attenuation active high override enable.
  [2:0] DRVCTRL_ATTEN_OVRD_VAL_PREG rw — When drvctrl_atten_ovrd_en_preg is asserted high, this value overrides the internally calculated attenuation for the transmit driver.
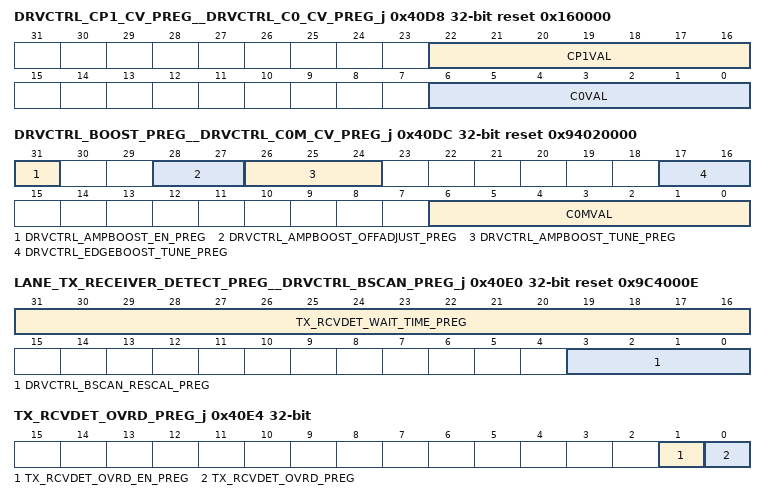
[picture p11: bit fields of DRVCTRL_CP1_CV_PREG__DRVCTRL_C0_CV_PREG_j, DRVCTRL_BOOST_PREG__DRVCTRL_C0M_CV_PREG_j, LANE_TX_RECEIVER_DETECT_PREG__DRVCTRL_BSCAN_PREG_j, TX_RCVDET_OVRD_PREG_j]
0x40D8 DRVCTRL_CP1_CV_PREG__DRVCTRL_C0_CV_PREG_j ro reset 0x160000 — Transmit driver main cursor status register. Offset = 40D8h + (j * 400h); where j = 0h to 1h
  [22:16] CP1VAL — Current post-emphasis cursor value to analog driver.
  [6:0] C0VAL — Current main cursor value to analog driver.
0x40DC DRVCTRL_BOOST_PREG__DRVCTRL_C0M_CV_PREG_j access per field reset 0x94020000 — Transmit driver margin status register. Offset = 40DCh + (j * 400h); where j = 0h to 1h
  [31] DRVCTRL_AMPBOOST_EN_PREG rw — Amplitude boost active high enable.
  [28:27] DRVCTRL_AMPBOOST_OFFADJUST_PREG rw — When amplitude boost is disabled, the calibrated resistor calibration value is increased by this value, compensating for the boost circuit impedance contribution no longer present.
  [26:24] DRVCTRL_AMPBOOST_TUNE_PREG rw — Amplitude boost selection:
  [17:16] DRVCTRL_EDGEBOOST_TUNE_PREG rw — Edge boost selection:
  [6:0] C0MVAL ro — Current margin value to analog driver.
0x40E0 LANE_TX_RECEIVER_DETECT_PREG__DRVCTRL_BSCAN_PREG_j reset 0x9C4000E — Transmit driver boundary scan resistor calibration override register. Offset = 40E0h + (j * 400h); where j = 0h to 1h
  [31:16] TX_RCVDET_WAIT_TIME_PREG — Receiver detection wait time:
  [3:0] DRVCTRL_BSCAN_RESCAL_PREG — Transmit driver resistor calibration level used in boundary scan operation.
0x40E4 TX_RCVDET_OVRD_PREG_j — Transmit driver receiver detection analog override Offset = 40E4h + (j * 400h); where j = 0h to 1h
  [1] TX_RCVDET_OVRD_EN_PREG — Receiver detection analog override enable:
  [0] TX_RCVDET_OVRD_PREG — Receiver detection analog override:
0x40E8 TXCOEF_STATUS_PREG_j ro — Transmit coefficient calculator status register. Offset = 40E8h + (j * 400h); where j = 0h to 1h
  [2:0] TXCOEF_STATE — Transmit coefficient calculator state vector.
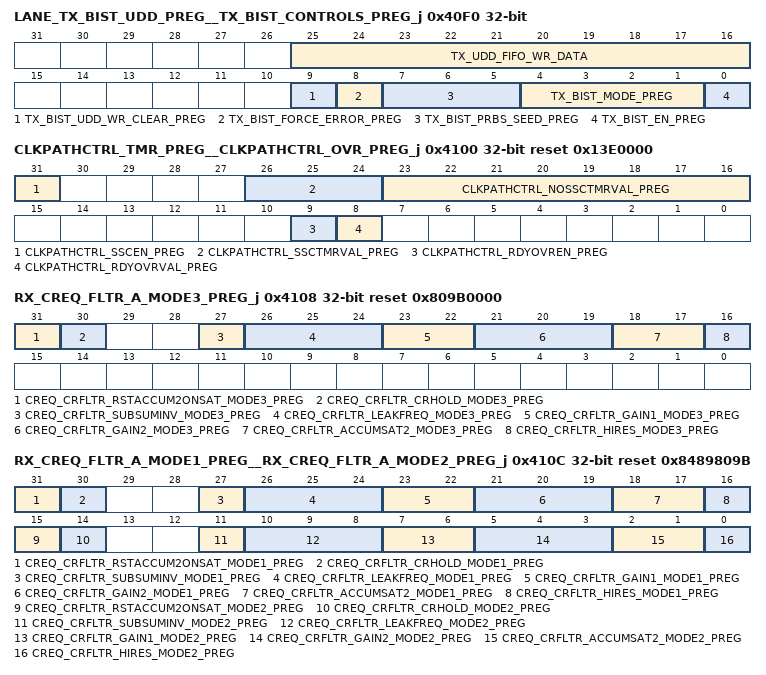
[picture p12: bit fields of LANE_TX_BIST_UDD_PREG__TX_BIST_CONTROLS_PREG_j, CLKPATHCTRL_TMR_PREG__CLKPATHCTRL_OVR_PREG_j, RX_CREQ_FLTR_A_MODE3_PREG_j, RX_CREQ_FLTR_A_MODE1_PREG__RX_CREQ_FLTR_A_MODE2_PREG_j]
0x40F0 LANE_TX_BIST_UDD_PREG__TX_BIST_CONTROLS_PREG_j access per field — Transmit BIST control register. Offset = 40F0h + (j * 400h); where j = 0h to 1h
  [25:16] TX_UDD_FIFO_WR_DATA wo — Transmit BIST user defined data:
  [9] TX_BIST_UDD_WR_CLEAR_PREG rw — Transmit BIST User Defined Data (UDD) FIFO write pointer clear:
  [8] TX_BIST_FORCE_ERROR_PREG wo — Transmit BIST force error toggle bit:
  [7:5] TX_BIST_PRBS_SEED_PREG rw — Transmit BIST PRBS seed:
  [4:1] TX_BIST_MODE_PREG rw — Transmit BIST mode:
  [0] TX_BIST_EN_PREG rw — Transmit BIST active high enable.
0x40F8 TX_LFPSGEN_STATUS_PREG_j ro — Transmit LFPS generator status register. Offset = 40F8h + (j * 400h); where j = 0h to 1h
  [3:0] TX_LFPSGEN_STATE — Transmit LFPS generator state vector.
0x4100 CLKPATHCTRL_TMR_PREG__CLKPATHCTRL_OVR_PREG_j reset 0x13E0000 — Receive clock path controller override register. Offset = 4100h + (j * 400h); where j = 0h to 1h
  [31] CLKPATHCTRL_SSCEN_PREG — Receive clock recovery timer selection
  [26:24] CLKPATHCTRL_SSCTMRVAL_PREG — Receive clock recovery lock timer with spread spectrum system
  [23:16] CLKPATHCTRL_NOSSCTMRVAL_PREG — Receive clock recovery lock timer without spread spectrum system
  [9] CLKPATHCTRL_RDYOVREN_PREG — Receive clock path ready signal to data path (deq_clkpathrdy) active high override enable.
  [8] CLKPATHCTRL_RDYOVRVAL_PREG — When clkpathctrl_rdyovren_preg is asserted high, this value will override the clock path controller generated ready signal (deq_ clkpathrdy).
0x4108 RX_CREQ_FLTR_A_MODE3_PREG_j reset 0x809B0000 — RX_CREQ_FLTR_A_MODE3_PREG Offset = 4108h + (j * 400h); where j = 0h to 1h
  [31] CREQ_CRFLTR_RSTACCUM2ONSAT_MODE3_PREG — Clock recovery filter 's integral path accumulator reset on saturation control when xcvr_standard_mode_ln_{15:0}[2:0] is 3'b011.
  [30] CREQ_CRFLTR_CRHOLD_MODE3_PREG — Clock recovery hold active high enable when xcvr_standard_mode_ln_{15:0}[2:0] is 3'b011.
  [27] CREQ_CRFLTR_SUBSUMINV_MODE3_PREG — Clock recovery filter inversion active high enable when xcvr_standard_mode_ln_{15:0}[2:0] is 3'b011.
  [26:24] CREQ_CRFLTR_LEAKFREQ_MODE3_PREG — Clock recovery integral path leak frequency when xcvr_standard_mode_ln_{15:0}[2:0] is 3'b011.
  [23:22] CREQ_CRFLTR_GAIN1_MODE3_PREG — Clock recovery combined proportional and integral path gain when xcvr_standard_mode_ln_{15:0}[2:0] is 3'b011.
  [21:19] CREQ_CRFLTR_GAIN2_MODE3_PREG — Clock recovery integral path gain when xcvr_standard_mode_ln_{15:0}[2:0] is 3'b011.
  [18:17] CREQ_CRFLTR_ACCUMSAT2_MODE3_PREG — Clock Recovery integral path accumulator saturation level when xcvr_standard_mode_ln_{15:0}[2:0] is 3'b011.
  [16] CREQ_CRFLTR_HIRES_MODE3_PREG — CPI high resolution enable when xcvr_standard_mode_ln_{15:0}[2:0] is 3'b011.
0x410C RX_CREQ_FLTR_A_MODE1_PREG__RX_CREQ_FLTR_A_MODE2_PREG_j reset 0x8489809B — RX_CREQ_FLTR_A_MODE1_PREG__RX_CREQ_FLTR_A_MODE2_PREG Offset = 410Ch + (j * 400h); where j = 0h to 1h
  [31] CREQ_CRFLTR_RSTACCUM2ONSAT_MODE1_PREG — Clock recovery filter 's integral path accumulator reset on saturation control when xcvr_standard_mode_ln_{15:0}[2:0] is 3'b001.
  [30] CREQ_CRFLTR_CRHOLD_MODE1_PREG — Clock recovery hold active high enable when xcvr_standard_mode_ln_{15:0}[2:0] is 3'b001.
  [27] CREQ_CRFLTR_SUBSUMINV_MODE1_PREG — Clock recovery filter inversion active high enable when xcvr_standard_mode_ln_{15:0}[2:0] is 3'b001.
  [26:24] CREQ_CRFLTR_LEAKFREQ_MODE1_PREG — Clock recovery integral path leak frequency when xcvr_standard_mode_ln_{15:0}[2:0] is 3'b001.
  [23:22] CREQ_CRFLTR_GAIN1_MODE1_PREG — Clock recovery combined proportional and integral path gain when xcvr_standard_mode_ln_{15:0}[2:0] is 3'b001.
  [21:19] CREQ_CRFLTR_GAIN2_MODE1_PREG — Clock recovery integral path gain when xcvr_standard_mode_ln_{15:0}[2:0] is 3'b001.
  [18:17] CREQ_CRFLTR_ACCUMSAT2_MODE1_PREG — Clock Recovery integral path accumulator saturation level when xcvr_standard_mode_ln_{15:0}[2:0] is 3'b001.
  [16] CREQ_CRFLTR_HIRES_MODE1_PREG — CPI high resolution enable when xcvr_standard_mode_ln_{15:0}[2:0] is 3'b001.
  [15] CREQ_CRFLTR_RSTACCUM2ONSAT_MODE2_PREG — Clock recovery filter 's integral path accumulator reset on saturation control when xcvr_standard_mode_ln_{15:0}[2:0] is 3'b010.
  [14] CREQ_CRFLTR_CRHOLD_MODE2_PREG — Clock recovery hold active high enable when xcvr_standard_mode_ln_{15:0}[2:0] is 3'b010.
  [11] CREQ_CRFLTR_SUBSUMINV_MODE2_PREG — Clock recovery filter inversion active high enable when xcvr_standard_mode_ln_{15:0}[2:0] is 3'b010.
  [10:8] CREQ_CRFLTR_LEAKFREQ_MODE2_PREG — Clock recovery integral path leak frequency when xcvr_standard_mode_ln_{15:0}[2:0] is 3'b010.
  [7:6] CREQ_CRFLTR_GAIN1_MODE2_PREG — Clock recovery combined proportional and integral path gain when xcvr_standard_mode_ln_{15:0}[2:0] is 3'b010.
  [5:3] CREQ_CRFLTR_GAIN2_MODE2_PREG — Clock recovery integral path gain when xcvr_standard_mode_ln_{15:0}[2:0] is 3'b010.
  [2:1] CREQ_CRFLTR_ACCUMSAT2_MODE2_PREG — Clock Recovery integral path accumulator saturation level when xcvr_standard_mode_ln_{15:0}[2:0] is 3'b010.
  [0] CREQ_CRFLTR_HIRES_MODE2_PREG — CPI high resolution enable when xcvr_standard_mode_ln_{15:0}[2:0] is 3'b010. Interpolation steps per UI
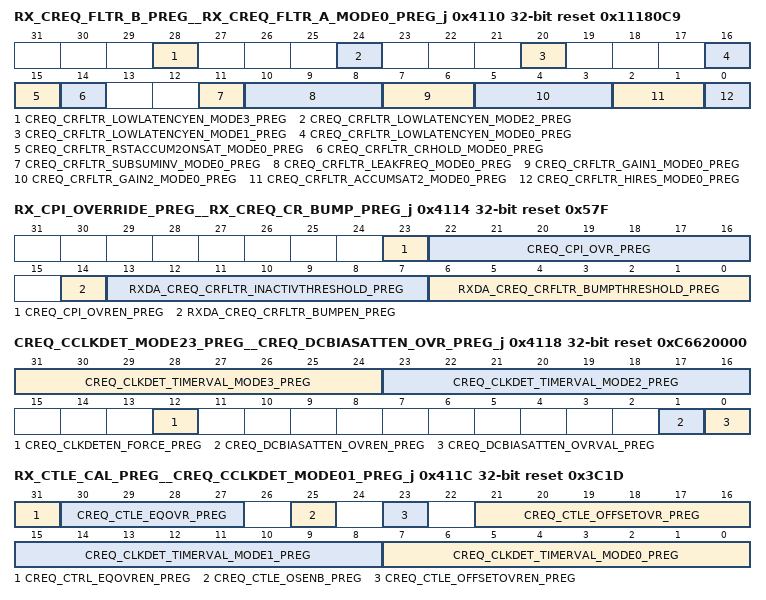
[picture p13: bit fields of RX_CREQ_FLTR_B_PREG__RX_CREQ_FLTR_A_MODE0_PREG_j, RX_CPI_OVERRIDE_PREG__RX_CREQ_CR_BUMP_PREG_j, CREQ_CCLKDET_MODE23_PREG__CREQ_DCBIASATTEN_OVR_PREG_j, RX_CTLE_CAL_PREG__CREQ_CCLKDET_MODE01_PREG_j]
0x4110 RX_CREQ_FLTR_B_PREG__RX_CREQ_FLTR_A_MODE0_PREG_j reset 0x11180C9 — Receive clock recovery filter control register A. Offset = 4110h + (j * 400h); where j = 0h to 1h
  [28] CREQ_CRFLTR_LOWLATENCYEN_MODE3_PREG — This value sets the low latency mode enable from the Lane Standards Decoder when xcvr_standard_mode_ln{15:0}[2:0] is 3'b011.
  [24] CREQ_CRFLTR_LOWLATENCYEN_MODE2_PREG — This value sets the low latency mode enable from the Lane Standards Decoder when xcvr_standard_mode_ln{15:0}[2:0] is 3'b010.
  [20] CREQ_CRFLTR_LOWLATENCYEN_MODE1_PREG — This value sets the low latency mode enable from the Lane Standards Decoder when xcvr_standard_mode_ln{15:0}[2:0] is 3'b001.
  [16] CREQ_CRFLTR_LOWLATENCYEN_MODE0_PREG — This value sets the low latency mode enable from the Lane Standards Decoder when xcvr_standard_mode_ln{15:0}[2:0] is 3'b000.
  [15] CREQ_CRFLTR_RSTACCUM2ONSAT_MODE0_PREG — Clock recovery filter 's integral path accumulator reset on saturation control when xcvr_standard_mode_ln_{15:0}[2:0] is 3'b000.
  [14] CREQ_CRFLTR_CRHOLD_MODE0_PREG — Clock recovery hold active high enable when xcvr_standard_mode_ln_{15:0}[2:0] is 3'b000.
  [11] CREQ_CRFLTR_SUBSUMINV_MODE0_PREG — Clock recovery filter inversion active high enable when xcvr_standard_mode_ln_{15:0}[2:0] is 3'b000.
  [10:8] CREQ_CRFLTR_LEAKFREQ_MODE0_PREG — Clock recovery integral path leak frequency when xcvr_standard_mode_ln_{15:0}[2:0] is 3'b000.
  [7:6] CREQ_CRFLTR_GAIN1_MODE0_PREG — Clock recovery combined proportional and integral path gain when xcvr_standard_mode_ln_{15:0}[2:0] is 3'b000.
  [5:3] CREQ_CRFLTR_GAIN2_MODE0_PREG — Clock recovery integral path gain when xcvr_standard_mode_ln_{15:0}[2:0] is 3'b000.
  [2:1] CREQ_CRFLTR_ACCUMSAT2_MODE0_PREG — Clock Recovery integral path accumulator saturation level: Limit
  [0] CREQ_CRFLTR_HIRES_MODE0_PREG — CPI high resolution enable when xcvr_standard_mode_ln_{15:0}[2:0] is 3'b000.
0x4114 RX_CPI_OVERRIDE_PREG__RX_CREQ_CR_BUMP_PREG_j reset 0x57F — Receive clock recovery bump feature control register. NOTE: The bump feature is deprecated. rxda_creq_crfltr_bumpen_preg should not be written high. Offset = 4114h + (j * 400h); where j = 0h to 1h
  [23] CREQ_CPI_OVREN_PREG — CPI phase active high override enable.
  [22:16] CREQ_CPI_OVR_PREG — When creq_cpi_ovren_preg is asserted high, this value will override the clock recovery filter CPI binary phase.
  [14] RXDA_CREQ_CRFLTR_BUMPEN_PREG — Clock recover bump feature active high enable.
  [13:7] RXDA_CREQ_CRFLTR_INACTIVTHRESHOLD_PREG — Clock recover bump feature inactivity threshold:
  [6:0] RXDA_CREQ_CRFLTR_BUMPTHRESHOLD_PREG — Clock recover bump feature bump threshold:
0x4118 CREQ_CCLKDET_MODE23_PREG__CREQ_DCBIASATTEN_OVR_PREG_j reset 0xC6620000 — Receive clock path DC bias attenuation override register. Offset = 4118h + (j * 400h); where j = 0h to 1h
  [31:24] CREQ_CLKDET_TIMERVAL_MODE3_PREG — This value sets the Lane Standards Decoder value when xcvr_standard_mode_{15:0}[2:0] is 3'b011.
  [23:16] CREQ_CLKDET_TIMERVAL_MODE2_PREG — This value sets the Lane Standards Decoder value when xcvr_standard_mode_{15:0}[2:0] is 3'b010.
  [12] CREQ_CLKDETEN_FORCE_PREG — When asserted, the ctleclk_clkdeten output of rxana_creq is forced high.
  [1] CREQ_DCBIASATTEN_OVREN_PREG — Clock path CTLE DC bias attenuation active high override enable.
  [0] CREQ_DCBIASATTEN_OVRVAL_PREG — When creq_dcbiasatten_ovren_preg is asserted high, this value overrides the internally generated control to ctleclk_dcbiasatten.
0x411C RX_CTLE_CAL_PREG__CREQ_CCLKDET_MODE01_PREG_j reset 0x3C1D — Receive clock path CTLE clock detection register for standard modes 0 and 1. Offset = 411Ch + (j * 400h); where j = 0h to 1h
  [31] CREQ_CTRL_EQOVREN_PREG — Receive clock path CTLE equalization pointer active high override enable.
  [30:27] CREQ_CTLE_EQOVR_PREG — When creq_ctrl_eqovren_preg is asserted high, this value overrides rxda_creq_eqptr in selecting the appropriate CTLE LUT entry.
  [25] CREQ_CTLE_OSENB_PREG — Receive clock path CTLE offset calibration algorithm active low maintenance enable.
  [23] CREQ_CTLE_OFFSETOVREN_PREG — Receive clock path CTLE offset calibration active high override enable.
  [21:16] CREQ_CTLE_OFFSETOVR_PREG — When creq_ctle_offsetovren_preg is asserted high, this value overrides the calibration algorithm binary data.
  [15:8] CREQ_CLKDET_TIMERVAL_MODE1_PREG — This value sets the Lane Standards Decoder value when xcvr_standard_mode_{15:0}[2:0] is 3'b001.
  [7:0] CREQ_CLKDET_TIMERVAL_MODE0_PREG — This value sets the Lane Standards Decoder value when xcvr_standard_mode_{15:0}[2:0] is 3'b000.
